# MKL82Z7 register map
Vendor: Freescale Semiconductor, Inc.; Series: Kinetis_L; File version: 1.6
CPU: CM0PLUS r0p0, little endian, no MPU, no FPU, VTOR, 2 interrupt priority bits
Registers are 32-bit, read-write, reset 0x0 unless marked. A register's access mark holds for its fields unless they carry their own. Offsets are from the block's base; [hi:lo] are bit positions; {n}, {i} and the like mark numbered series; 'fields as' and 'values as' point back to an identical list.

## RCM — Reset Control Module
Base 0x4007F000; register names take the prefix RCM_
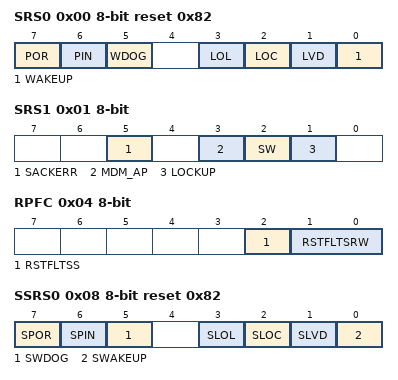
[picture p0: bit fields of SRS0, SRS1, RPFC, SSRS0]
0x00 SRS0 8-bit ro reset 0x82 — System Reset Status Register 0
  [7] POR — Power-On Reset
    0=Reset not caused by POR; 1=Reset caused by POR
  [6] PIN — External Reset Pin
    0=Reset not caused by external reset pin; 1=Reset caused by external reset pin
  [5] WDOG — Watchdog
    0=Reset not caused by watchdog timeout; 1=Reset caused by watchdog timeout
  [3] LOL — Loss-of-Lock Reset
    0=Reset not caused by a loss of lock in the PLL; 1=Reset caused by a loss of lock in the PLL
  [2] LOC — Loss-of-Clock Reset
    0=Reset not caused by a loss of external clock; 1=Reset caused by a loss of external clock
  [1] LVD — Low-Voltage Detect Reset
    0=Reset not caused by LVD trip or POR; 1=Reset caused by LVD trip or POR
  [0] WAKEUP — Low Leakage Wakeup Reset
    0=Reset not caused by LLWU module wakeup source; 1=Reset caused by LLWU module wakeup source
0x01 SRS1 8-bit ro — System Reset Status Register 1
  [5] SACKERR — Stop Mode Acknowledge Error Reset
    0=Reset not caused by peripheral failure to acknowledge attempt to enter stop mode; 1=Reset caused by peripheral failure to acknowledge attempt to enter stop mode
  [3] MDM_AP — MDM-AP System Reset Request
    0=Reset not caused by host debugger system setting of the System Reset Request bit; 1=Reset caused by host debugger system setting of the System Reset Request bit
  [2] SW — Software
    0=Reset not caused by software setting of SYSRESETREQ bit; 1=Reset caused by software setting of SYSRESETREQ bit
  [1] LOCKUP — Core Lockup
    0=Reset not caused by core LOCKUP event; 1=Reset caused by core LOCKUP event
0x04 RPFC 8-bit — Reset Pin Filter Control register
  [2] RSTFLTSS — Reset Pin Filter Select in Stop Mode
    0=All filtering disabled; 1=LPO clock filter enabled
  [1:0] RSTFLTSRW — Reset Pin Filter Select in Run and Wait Modes
    0=All filtering disabled; 1=Bus clock filter enabled for normal operation; 2=LPO clock filter enabled for normal operation
0x05 RPFW 8-bit — Reset Pin Filter Width register
  [4:0] RSTFLTSEL — Reset Pin Filter Bus Clock Select
    {v}=Bus clock filter count is {v+1} (v=0..31)
0x06 FM 8-bit — Force Mode Register
  [2:1] FORCEROM — Force ROM Boot
    0=No effect; 1=Force boot from ROM with RCM_MR[1] set; 2=Force boot from ROM with RCM_MR[2] set; 3=Force boot from ROM with RCM_MR[2:1] set
0x07 MR 8-bit — Mode Register
  [2:1] BOOTROM — Boot ROM Configuration
    0=Boot from Flash; 1=Boot from ROM due to BOOTCFG0 pin assertion; 2=Boot form ROM due to FOPT[7] configuration; 3=Boot from ROM due to both BOOTCFG0 pin assertion and FOPT[7] configuration
0x08 SSRS0 8-bit reset 0x82 — Sticky System Reset Status Register 0
  [7] SPOR — Sticky Power-On Reset
    0=Reset not caused by POR; 1=Reset caused by POR
  [6] SPIN — Sticky External Reset Pin
    values as SRS0.PIN
  [5] SWDOG — Sticky Watchdog
    values as SRS0.WDOG
  [3] SLOL — Sticky Loss-of-Lock Reset
    values as SRS0.LOL
  [2] SLOC — Sticky Loss-of-Clock Reset
    values as SRS0.LOC
  [1] SLVD — Sticky Low-Voltage Detect Reset
    values as SRS0.LVD
  [0] SWAKEUP — Sticky Low Leakage Wakeup Reset
    values as SRS0.WAKEUP
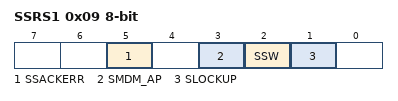
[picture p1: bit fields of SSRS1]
0x09 SSRS1 8-bit — Sticky System Reset Status Register 1
  [5] SSACKERR — Sticky Stop Mode Acknowledge Error Reset
    values as SRS1.SACKERR
  [3] SMDM_AP — Sticky MDM-AP System Reset Request
    values as SRS1.MDM_AP
  [2] SSW — Sticky Software
    values as SRS1.SW
  [1] SLOCKUP — Sticky Core Lockup
    values as SRS1.LOCKUP

## GPIOA — General Purpose Input/Output
Base 0x400FF000; register names take the prefix GPIOA_
0x00 PDOR — Port Data Output Register
  [31:0] PDO — Port Data Output
    0=Logic level 0 is driven on pin, provided pin is configured for general-purpose output; 1=Logic level 1 is driven on pin, provided pin is configured for general-purpose output
0x04 PSOR wo — Port Set Output Register
  [31:0] PTSO — Port Set Output
    0=Corresponding bit in PDORn does not change; 1=Corresponding bit in PDORn is set to logic 1
0x08 PCOR wo — Port Clear Output Register
  [31:0] PTCO — Port Clear Output
    0=Corresponding bit in PDORn does not change; 1=Corresponding bit in PDORn is cleared to logic 0
0x0C PTOR wo — Port Toggle Output Register
  [31:0] PTTO — Port Toggle Output
    0=Corresponding bit in PDORn does not change; 1=Corresponding bit in PDORn is set to the inverse of its existing logic state
0x10 PDIR ro — Port Data Input Register
  [31:0] PDI — Port Data Input
    0=Pin logic level is logic 0, or is not configured for use by digital function; 1=Pin logic level is logic 1
0x14 PDDR — Port Data Direction Register
  [31:0] PDD — Port Data Direction
    0=Pin is configured as general-purpose input, for the GPIO function; 1=Pin is configured as general-purpose output, for the GPIO function

## GPIOB — General Purpose Input/Output
Base 0x400FF040; register names take the prefix GPIOB_
Registers as GPIOA.

## GPIOC — General Purpose Input/Output
Base 0x400FF080; register names take the prefix GPIOC_
Registers as GPIOA.

## GPIOD — General Purpose Input/Output
Base 0x400FF0C0; register names take the prefix GPIOD_
Registers as GPIOA.

## GPIOE — General Purpose Input/Output
Base 0x400FF100; register names take the prefix GPIOE_
Registers as GPIOA.

## FGPIOA — General Purpose Input/Output
Base 0xF8000000; register names take the prefix FGPIOA_
Registers as GPIOA.

## FGPIOB — General Purpose Input/Output
Base 0xF8000040; register names take the prefix FGPIOB_
Registers as GPIOA.

## FGPIOC — General Purpose Input/Output
Base 0xF8000080; register names take the prefix FGPIOC_
Registers as GPIOA.

## FGPIOD — General Purpose Input/Output
Base 0xF80000C0; register names take the prefix FGPIOD_
Registers as GPIOA.

## FGPIOE — General Purpose Input/Output
Base 0xF8000100; register names take the prefix FGPIOE_
Registers as GPIOA.
